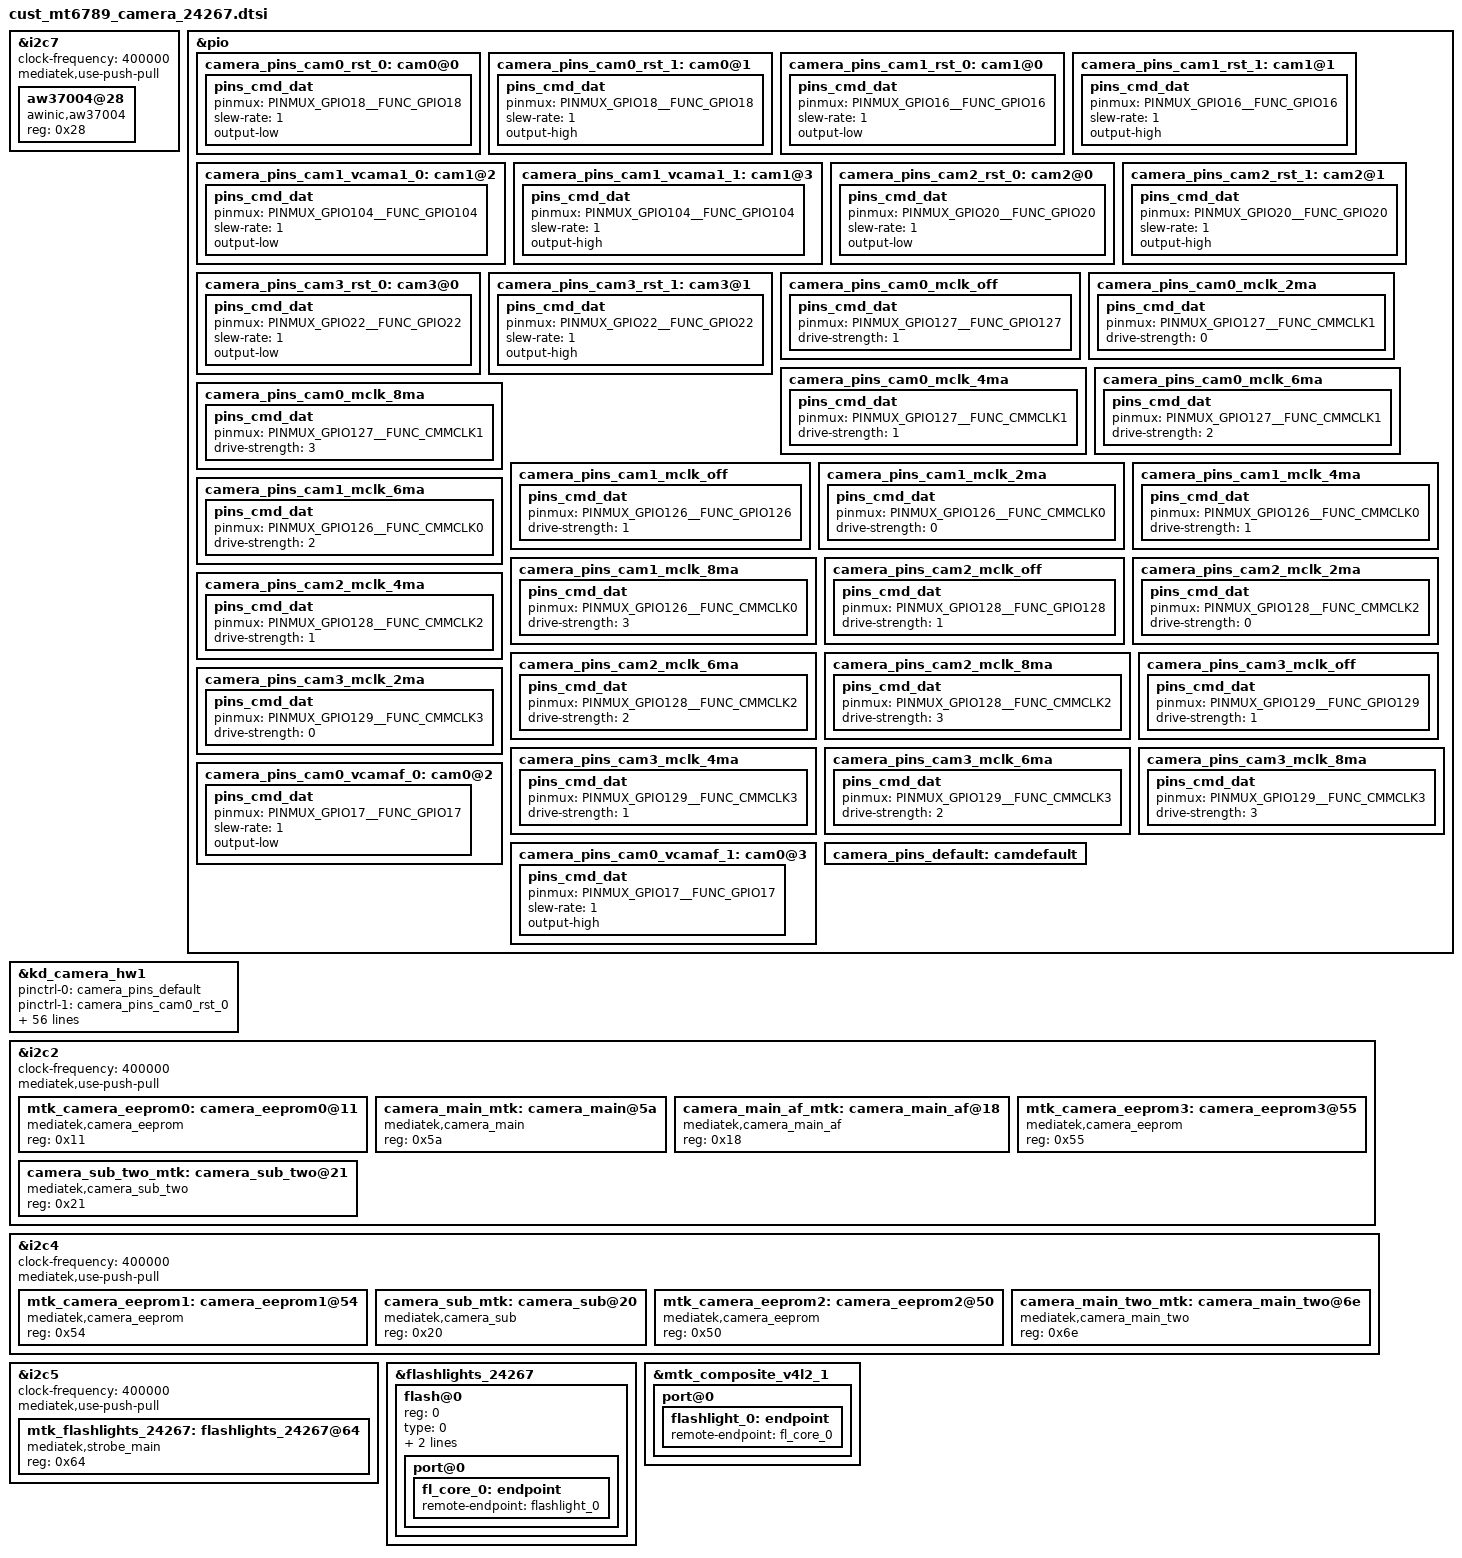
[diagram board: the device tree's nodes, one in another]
// SPDX-License-Identifier: GPL-2.0
/* Copyright (c) 2020 MediaTek Inc. */
/* CAMERA GPIO standardization */

/* CAMERA AW37004DNR*/
&i2c7 {
	status = "okay";
	clock-frequency = <400000>;
	mediatek,use-push-pull;
	#address-cells = <1>;
	#size-cells = <0>;
	aw37004@28{
		compatible = "awinic,aw37004";
		reg = <0x28>;
		status = "okay";
	};
};
/* CAMERA AW37004DNR END*/

/*camera power pinctrl*/
&pio {
	camera_pins_cam0_rst_0: cam0@0 {
		pins_cmd_dat {
			pinmux = <PINMUX_GPIO18__FUNC_GPIO18>;
			slew-rate = <1>;
			output-low;
		};
	};
	camera_pins_cam0_rst_1: cam0@1 {
		pins_cmd_dat {
			pinmux = <PINMUX_GPIO18__FUNC_GPIO18>;
			slew-rate = <1>;
			output-high;
		};
	};
	camera_pins_cam1_rst_0: cam1@0 {
		pins_cmd_dat {
			pinmux = <PINMUX_GPIO16__FUNC_GPIO16>;
			slew-rate = <1>;
			output-low;
		};
	};
	camera_pins_cam1_rst_1: cam1@1 {
		pins_cmd_dat {
			pinmux = <PINMUX_GPIO16__FUNC_GPIO16>;
			slew-rate = <1>;
			output-high;
		};
	};
	camera_pins_cam1_vcama1_0: cam1@2 {
		pins_cmd_dat {
			pinmux = <PINMUX_GPIO104__FUNC_GPIO104>;
			slew-rate = <1>;
			output-low;
		};
	};
	camera_pins_cam1_vcama1_1: cam1@3 {
		pins_cmd_dat {
			pinmux = <PINMUX_GPIO104__FUNC_GPIO104>;
			slew-rate = <1>;
			output-high;
		};
	};
	camera_pins_cam2_rst_0: cam2@0 {
		pins_cmd_dat {
			pinmux = <PINMUX_GPIO20__FUNC_GPIO20>;
			slew-rate = <1>;
			output-low;
		};
	};
	camera_pins_cam2_rst_1: cam2@1 {
		pins_cmd_dat {
			pinmux = <PINMUX_GPIO20__FUNC_GPIO20>;
			slew-rate = <1>;
			output-high;
		};
	};
	camera_pins_cam3_rst_0: cam3@0 {
		pins_cmd_dat {
			pinmux = <PINMUX_GPIO22__FUNC_GPIO22>;
			slew-rate = <1>;
			output-low;
		};
	};
	camera_pins_cam3_rst_1: cam3@1 {
		pins_cmd_dat {
			pinmux = <PINMUX_GPIO22__FUNC_GPIO22>;
			slew-rate = <1>;
			output-high;
		};
	};
	camera_pins_cam0_mclk_off: camera_pins_cam0_mclk_off {
		pins_cmd_dat {
			pinmux = <PINMUX_GPIO127__FUNC_GPIO127>;
			drive-strength = <1>;
		};
	};
	camera_pins_cam0_mclk_2ma: camera_pins_cam0_mclk_2ma {
		pins_cmd_dat {
			pinmux = <PINMUX_GPIO127__FUNC_CMMCLK1>;
			drive-strength = <0>;
		};
	};
	camera_pins_cam0_mclk_4ma: camera_pins_cam0_mclk_4ma {
		pins_cmd_dat {
			pinmux = <PINMUX_GPIO127__FUNC_CMMCLK1>;
			drive-strength = <1>;
		};
	};
	camera_pins_cam0_mclk_6ma: camera_pins_cam0_mclk_6ma {
		pins_cmd_dat {
			pinmux = <PINMUX_GPIO127__FUNC_CMMCLK1>;
			drive-strength = <2>;
		};
	};
	camera_pins_cam0_mclk_8ma: camera_pins_cam0_mclk_8ma {
		pins_cmd_dat {
			pinmux = <PINMUX_GPIO127__FUNC_CMMCLK1>;
			drive-strength = <3>;
		};
	};
	camera_pins_cam1_mclk_off: camera_pins_cam1_mclk_off {
		pins_cmd_dat {
			pinmux = <PINMUX_GPIO126__FUNC_GPIO126>;
			drive-strength = <1>;
		};
	};
	camera_pins_cam1_mclk_2ma: camera_pins_cam1_mclk_2ma {
		pins_cmd_dat {
			pinmux = <PINMUX_GPIO126__FUNC_CMMCLK0>;
			drive-strength = <0>;
		};
	};
	camera_pins_cam1_mclk_4ma: camera_pins_cam1_mclk_4ma {
		pins_cmd_dat {
			pinmux = <PINMUX_GPIO126__FUNC_CMMCLK0>;
			drive-strength = <1>;
		};
	};
	camera_pins_cam1_mclk_6ma: camera_pins_cam1_mclk_6ma {
		pins_cmd_dat {
			pinmux = <PINMUX_GPIO126__FUNC_CMMCLK0>;
			drive-strength = <2>;
		};
	};
	camera_pins_cam1_mclk_8ma: camera_pins_cam1_mclk_8ma {
		pins_cmd_dat {
			pinmux = <PINMUX_GPIO126__FUNC_CMMCLK0>;
			drive-strength = <3>;
		};
	};
	camera_pins_cam2_mclk_off: camera_pins_cam2_mclk_off {
		pins_cmd_dat {
			pinmux = <PINMUX_GPIO128__FUNC_GPIO128>;
			drive-strength = <1>;
		};
	};
	camera_pins_cam2_mclk_2ma: camera_pins_cam2_mclk_2ma {
		pins_cmd_dat {
			pinmux = <PINMUX_GPIO128__FUNC_CMMCLK2>;
			drive-strength = <0>;
		};
	};
	camera_pins_cam2_mclk_4ma: camera_pins_cam2_mclk_4ma {
		pins_cmd_dat {
			pinmux = <PINMUX_GPIO128__FUNC_CMMCLK2>;
			drive-strength = <1>;
		};
	};
	camera_pins_cam2_mclk_6ma: camera_pins_cam2_mclk_6ma {
		pins_cmd_dat {
			pinmux = <PINMUX_GPIO128__FUNC_CMMCLK2>;
			drive-strength = <2>;
		};
	};
	camera_pins_cam2_mclk_8ma: camera_pins_cam2_mclk_8ma {
		pins_cmd_dat {
			pinmux = <PINMUX_GPIO128__FUNC_CMMCLK2>;
			drive-strength = <3>;
		};
	};
	camera_pins_cam3_mclk_off: camera_pins_cam3_mclk_off {
		pins_cmd_dat {
			pinmux = <PINMUX_GPIO129__FUNC_GPIO129>;
			drive-strength = <1>;
		};
	};
	camera_pins_cam3_mclk_2ma: camera_pins_cam3_mclk_2ma {
		pins_cmd_dat {
			pinmux = <PINMUX_GPIO129__FUNC_CMMCLK3>;
			drive-strength = <0>;
		};
	};
	camera_pins_cam3_mclk_4ma: camera_pins_cam3_mclk_4ma {
		pins_cmd_dat {
			pinmux = <PINMUX_GPIO129__FUNC_CMMCLK3>;
			drive-strength = <1>;
		};
	};
	camera_pins_cam3_mclk_6ma: camera_pins_cam3_mclk_6ma {
		pins_cmd_dat {
			pinmux = <PINMUX_GPIO129__FUNC_CMMCLK3>;
			drive-strength = <2>;
		};
	};
	camera_pins_cam3_mclk_8ma: camera_pins_cam3_mclk_8ma {
		pins_cmd_dat {
			pinmux = <PINMUX_GPIO129__FUNC_CMMCLK3>;
			drive-strength = <3>;
		};
	};
	camera_pins_cam0_vcamaf_0: cam0@2 {
		pins_cmd_dat {
			pinmux = <PINMUX_GPIO17__FUNC_GPIO17>;
			slew-rate = <1>;
			output-low;
		};
	};
	camera_pins_cam0_vcamaf_1: cam0@3 {
		pins_cmd_dat {
			pinmux = <PINMUX_GPIO17__FUNC_GPIO17>;
			slew-rate = <1>;
			output-high;
		};
	};
	camera_pins_default: camdefault {
	};
};
&kd_camera_hw1 {
	pinctrl-names = "default",
			"cam0_rst0", "cam0_rst1",
			"cam1_rst0", "cam1_rst1",
			"cam2_rst0", "cam2_rst1",
			"cam3_rst0", "cam3_rst1",
			"cam0_mclk_off",
			"cam0_mclk_2mA", "cam0_mclk_4mA",
			"cam0_mclk_6mA", "cam0_mclk_8mA",
			"cam1_mclk_off",
			"cam1_mclk_2mA", "cam1_mclk_4mA",
			"cam1_mclk_6mA", "cam1_mclk_8mA",
			"cam2_mclk_off",
			"cam2_mclk_2mA", "cam2_mclk_4mA",
			"cam2_mclk_6mA", "cam2_mclk_8mA",
			"cam3_mclk_off",
			"cam3_mclk_2mA", "cam3_mclk_4mA",
			"cam3_mclk_6mA", "cam3_mclk_8mA",
			"cam0_ldo_vcamafvdd_0", "cam0_ldo_vcamafvdd_1",
			"cam1_ldo_vcama1_0", "cam1_ldo_vcama1_1";

	pinctrl-0 = <&camera_pins_default>;
	pinctrl-1 = <&camera_pins_cam0_rst_0>;
	pinctrl-2 = <&camera_pins_cam0_rst_1>;
	pinctrl-3 = <&camera_pins_cam1_rst_0>;
	pinctrl-4 = <&camera_pins_cam1_rst_1>;
	pinctrl-5 = <&camera_pins_cam2_rst_0>;
	pinctrl-6 = <&camera_pins_cam2_rst_1>;
	pinctrl-7 = <&camera_pins_cam3_rst_0>;
	pinctrl-8 = <&camera_pins_cam3_rst_1>;
	pinctrl-9 = <&camera_pins_cam0_mclk_off>;
	pinctrl-10 = <&camera_pins_cam0_mclk_2ma>;
	pinctrl-11 = <&camera_pins_cam0_mclk_4ma>;
	pinctrl-12 = <&camera_pins_cam0_mclk_6ma>;
	pinctrl-13 = <&camera_pins_cam0_mclk_8ma>;
	pinctrl-14 = <&camera_pins_cam1_mclk_off>;
	pinctrl-15 = <&camera_pins_cam1_mclk_2ma>;
	pinctrl-16 = <&camera_pins_cam1_mclk_4ma>;
	pinctrl-17 = <&camera_pins_cam1_mclk_6ma>;
	pinctrl-18 = <&camera_pins_cam1_mclk_8ma>;
	pinctrl-19 = <&camera_pins_cam2_mclk_off>;
	pinctrl-20 = <&camera_pins_cam2_mclk_2ma>;
	pinctrl-21 = <&camera_pins_cam2_mclk_4ma>;
	pinctrl-22 = <&camera_pins_cam2_mclk_6ma>;
	pinctrl-23 = <&camera_pins_cam2_mclk_8ma>;
	pinctrl-24 = <&camera_pins_cam3_mclk_off>;
	pinctrl-25 = <&camera_pins_cam3_mclk_2ma>;
	pinctrl-26 = <&camera_pins_cam3_mclk_4ma>;
	pinctrl-27 = <&camera_pins_cam3_mclk_6ma>;
	pinctrl-28 = <&camera_pins_cam3_mclk_8ma>;
	pinctrl-29 = <&camera_pins_cam0_vcamaf_0>;
	pinctrl-30 = <&camera_pins_cam0_vcamaf_1>;
	pinctrl-31 = <&camera_pins_cam1_vcama1_0>;
	pinctrl-32 = <&camera_pins_cam1_vcama1_1>;


	cam0_pin_mclk = "mclk";
	cam0_pin_rst = "gpio";
	cam0_pin_vcama = "aw37004";
	cam0_pin_vcamio = "aw37004";
	cam0_pin_vcamd = "aw37004";
	cam0_pin_vcamaf = "gpio";
	cam1_pin_mclk = "mclk";
	cam1_pin_rst = "gpio";
	cam1_pin_vcama1 = "gpio";
	cam1_pin_vcama = "aw37004";
	cam1_pin_vcamio = "aw37004";
	cam1_pin_vcamd = "aw37004";
	cam2_pin_mclk = "mclk";
	cam2_pin_rst = "gpio";
	cam2_pin_vcama = "aw37004";
	cam2_pin_vcamio = "aw37004";
	cam2_pin_vcamd = "aw37004";
	cam3_pin_mclk = "mclk";
	cam3_pin_rst = "gpio";
	cam3_pin_vcama = "aw37004";
	cam3_pin_vcamio = "aw37004";

	cam0_enable_sensor = "ov50d40_mipi_raw_24267";
	cam1_enable_sensor = "gc32e2_mipi_raw_24267";
	cam2_enable_sensor = "ov08d10_mipi_raw_24267";
	cam3_enable_sensor = "ov02b10_mipi_raw_24267";
	status = "okay";
};
/* CAMERA GPIO end */

/* CAMERA EEPROM */
&i2c2 {
	status = "okay";
	clock-frequency = <400000>;
	mediatek,use-push-pull;
	#address-cells = <1>;
	#size-cells = <0>;

	mtk_camera_eeprom0:camera_eeprom0@11 {
		compatible = "mediatek,camera_eeprom";
		reg = <0x11>;
		status = "okay";
	};
	camera_main_mtk:camera_main@5a {
		compatible = "mediatek,camera_main";
		#thermal-sensor-cells = <0>;
		reg = <0x5a>;
		status = "okay";
	};
	camera_main_af_mtk:camera_main_af@18 {
		compatible = "mediatek,camera_main_af";
		reg = <0x18>;
		status = "okay";
	};
	mtk_camera_eeprom3:camera_eeprom3@55 {
		compatible = "mediatek,camera_eeprom";
		reg = <0x55>;
		status = "okay";
	};
	camera_sub_two_mtk:camera_sub_two@21 {
		compatible = "mediatek,camera_sub_two";
		#thermal-sensor-cells = <0>;
		reg = <0x21>;
		status = "okay";
	};
};

&i2c4 {
	status = "okay";
	clock-frequency = <400000>;
	mediatek,use-push-pull;
	#address-cells = <1>;
	#size-cells = <0>;

	mtk_camera_eeprom1:camera_eeprom1@54 {
		compatible = "mediatek,camera_eeprom";
		reg = <0x54>;
		status = "okay";
	};
	camera_sub_mtk:camera_sub@20 {
		compatible = "mediatek,camera_sub";
		#thermal-sensor-cells = <0>;
		reg = <0x20>;
		status = "okay";
	};
	mtk_camera_eeprom2:camera_eeprom2@50 {
		compatible = "mediatek,camera_eeprom";
		reg = <0x50>;
		status = "okay";
	};
	camera_main_two_mtk:camera_main_two@6e {
		compatible = "mediatek,camera_main_two";
		#thermal-sensor-cells = <0>;
		reg = <0x6e>;
		status = "okay";
	};
};

&i2c5 {
	status = "okay";
	clock-frequency = <400000>;
	mediatek,use-push-pull;

	mtk_flashlights_24267:flashlights_24267@64 {
		compatible = "mediatek,strobe_main";
		reg = <0x64>;
		status = "okay";
	};
};

&flashlights_24267 {
	status = "okay";
	flash@0{
		reg = <0>;
		type = <0>;
		ct = <0>;
		part = <0>;
		port@0 {
			fl_core_0: endpoint {
				remote-endpoint = <&flashlight_0>;
			};
		};
	};
};

&mtk_composite_v4l2_1 {
	port@0 {
		flashlight_0: endpoint {
			remote-endpoint = <&fl_core_0>;
		};
	};
};

/* CAMERA EEPROM end */
